# S6E2D5 register map
File version: 1.1
CPU: CM4 r0p1, little endian, MPU, FPU, 4 interrupt priority bits
Registers are 32-bit, read-write, reset 0x0 unless marked. A register's access mark holds for its fields unless they carry their own. Offsets are from the block's base; [hi:lo] are bit positions.

## CRC — CRC Registers
Base 0x40039000
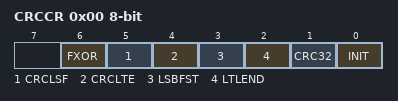
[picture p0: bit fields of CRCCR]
0x00 CRCCR 8-bit — CRC Control Register
  [6] FXOR — Initialization bit
  [5] CRCLSF — Final XOR control bit
  [4] CRCLTE — CRC result bit-order setting bit
  [3] LSBFST — CRC result byte-order setting bit
  [2] LTLEND — Bit-order setting bit
  [1] CRC32 — Byte-order setting bit
  [0] INIT — CRC mode selection bit
0x04 CRCINIT reset 0xFFFFFFFF — Initial Value Register
  [31:0] D — Initial value
0x08 CRCIN — Input Data Register
  [31:0] D — Input data
0x0C CRCR ro reset 0xFFFFFFFF — CRC Register
  [31:0] D — CRC Data

## WC — Watch Counter
Base 0x4003A000
0x00 WCRD 8-bit ro — Watch Counter Read Register
  [5:0] CTR — Counter read bits
0x01 WCRL 8-bit — Watch Counter Reload Register
  [5:0] RLC — Counter reload value setting bits
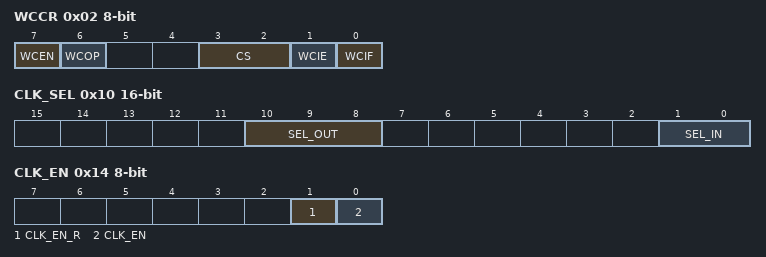
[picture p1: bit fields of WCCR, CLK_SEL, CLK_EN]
0x02 WCCR 8-bit — Watch Counter Control Register
  [7] WCEN — Watch counter operation enable bit
  [6] WCOP ro — Watch counter operating state flag
  [3:2] CS — Count clock select bits
  [1] WCIE — Interrupt request enable bit
  [0] WCIF — Interrupt request flag bit
0x10 CLK_SEL 16-bit — Clock Selection Register
  [10:8] SEL_OUT — Output clock selection bit
  [1:0] SEL_IN — Input clock selection bit
0x14 CLK_EN 8-bit — Division Clock Enable Register
  [1] CLK_EN_R — Division clock enable read bit
  [0] CLK_EN — Division clock enable bit

## LCR — Low-speed CR Prescaler
Base 0x4003C000
0x00 LCR_PRSLD 8-bit — Low-speed CR Prescaler Control Register
  [5:0] LCR_PRSLD — Low-speed CR Prescaler Load

## I2SPRE — I2S Clock Generation
Base 0x4003D000
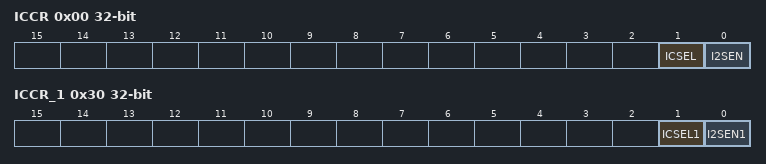
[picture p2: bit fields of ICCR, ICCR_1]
0x00 ICCR — I2S Clock Control Register
  [1] ICSEL — I2S clock selection bit
  [0] I2SEN — I2S clock output enable bit
0x04 IPCR1 — I2S-PLL Control Register 1
  [0] IPLLEN — I2S-PLL oscillation enable bit
0x08 IPCR2 — I2S-PLL Control Register 2
  [2:0] IPOWT — I2S-PLL oscillation stabilization wait time setting bits
0x0C IPCR3 reset 0x1 — I2S-PLL Control Register 3
  [4:0] IPLLK — Frequency division ratio (K) setting bits of the I2S-PLL clock
0x10 IPCR4 reset 0x1F — I2S-PLL Control Register 4
  [6:0] IPLLN — Frequency division ratio (N) setting bits of the I2S-PLL clock
0x14 IP_STR ro — I2S-PLL Status Register
  [0] IPRDY — I2S-PLL oscillation stabilization bit
0x18 IPINT_ENR — I2S-PLL Interrupt Factor Enable Register
  [0] IPCSE — I2S-PLL oscillation stabilization wait complete interrupt enable bit
0x1C IPINT_CLR wo — I2S-PLL Interrupt Factor Status Register
  [0] IPCSC — I2S-PLL interrupt factor status bit
0x20 IPINT_STR ro — I2S-PLL Interrupt Factor Clear Register
  [0] IPCSI — I2S-PLL oscillation stabilization interrupt factor clear bit
0x24 IPCR5 reset 0x18 — I2S-PLL Control Register 5
  [6:0] IPLLM — Frequency division ratio (M) setting bits of the I2S-PLL clock
0x30 ICCR_1 — I2S Clock Control Register
  [1] ICSEL1 — I2S clock selection bit
  [0] I2SEN1 — I2S clock output enable bit
0x34 IPCR5_1 reset 0x18 — I2S-PLL Control Register 5
  [6:0] IPLLM1 — Frequency division ratio (M) setting bits of the I2S-PLL clock

## GDCPRE — GDC Prescaler
Base 0x4003D100
0x00 GCCR — GSS Clock Control Register
  [0] GSSEN — GSS clock output enable/disable setting bit
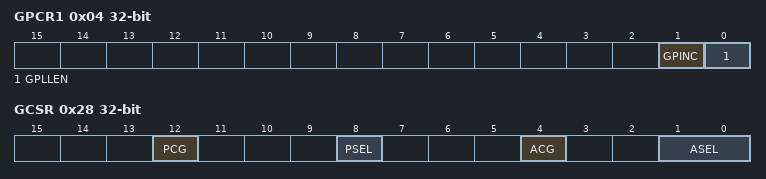
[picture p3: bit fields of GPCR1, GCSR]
0x04 GPCR1 — GSS PLL Control Register 1
  [1] GPINC — GDC PLL input clock selection bit
  [0] GPLLEN — GDC PLL enable/disable setting bit
0x08 GPCR2 — GSS PLL Control Register 2
  [2:0] GPOWT — PLL clock stabilization wait time set up bits
0x0C GPCR3 — GSS PLL Control Register 3
  [4:0] GPLLK — PLL input clock frequency division ratio setting bits
0x10 GPCR4 — GSS PLL Control Register 4
  [6:0] GPLLN — PLL feedback frequency division rasio seting bits
0x14 GP_STR ro — GSS PLL Status Register
  [0] GPRDY — GDC PLL status bit
0x18 GPINT_ENR — GSS PLL Interrupt Enable Register
  [0] GPCSE — PLL oscillation stabilization wait completion interrupt enable bit
0x1C GPINT_CLR — GSS PLL Interrupt Clear Register
  [0] GPCSC — GDC PLL oscillation stabilization wait completion interrupt clear bit
0x20 GPINT_STR ro — GSS PLL Status Register
  [0] GPCSI — GDC PLL oscillation stabilization wait completion interrupt status bit
0x28 GCSR — GSS Clock Select Register
  [12] PCG — HCLK Clock gating for Reference clock for Peripherals setting bit
  [8] PSEL — Peripheral clock for the GDC Sub system selection bit
  [4] ACG — Clock gating for Reference clock for GDC clock setting bit
  [1:0] ASEL — Reference clock for the GDC clock selection bits
0x2C GRCR — GSS Reset Control Register
  [0] RSTEN — Software reset for the GDC Sub system setting bit
0x30 GMCR — GSS Mode Control Register
  [0] TEN — PLL oscillation under case of TIMER mode control bit

## Notices in the file
Copyright (C) 2015 Spansion LLC. All Rights Reserved.
This software is owned and published by:
Spansion LLC, 915 DeGuigne Dr. Sunnyvale, CA  94088-3453 ("Spansion").
BY DOWNLOADING, INSTALLING OR USING THIS SOFTWARE, YOU AGREE TO BE BOUND
BY ALL THE TERMS AND CONDITIONS OF THIS AGREEMENT.
This software contains source code for use with Spansion
components. This software is licensed by Spansion to be adapted only
for use in systems utilizing Spansion components. Spansion shall not be
responsible for misuse or illegal use of this software for devices not
supported herein.  Spansion is providing this software "AS IS" and will
not be responsible for issues arising from incorrect user implementation
of the software.
SPANSION MAKES NO WARRANTY, EXPRESS OR IMPLIED, ARISING BY LAW OR OTHERWISE,
REGARDING THE SOFTWARE (INCLUDING ANY ACOOMPANYING WRITTEN MATERIALS),
ITS PERFORMANCE OR SUITABILITY FOR YOUR INTENDED USE, INCLUDING,
WITHOUT LIMITATION, THE IMPLIED WARRANTY OF MERCHANTABILITY, THE IMPLIED
WARRANTY OF FITNESS FOR A PARTICULAR PURPOSE OR USE, AND THE IMPLIED
WARRANTY OF NONINFRINGEMENT.
SPANSION SHALL HAVE NO LIABILITY (WHETHER IN CONTRACT, WARRANTY, TORT,
NEGLIGENCE OR OTHERWISE) FOR ANY DAMAGES WHATSOEVER (INCLUDING, WITHOUT
LIMITATION, DAMAGES FOR LOSS OF BUSINESS PROFITS, BUSINESS INTERRUPTION,
LOSS OF BUSINESS INFORMATION, OR OTHER PECUNIARY LOSS) ARISING FROM USE OR
INABILITY TO USE THE SOFTWARE, INCLUDING, WITHOUT LIMITATION, ANY DIRECT,
INDIRECT, INCIDENTAL, SPECIAL OR CONSEQUENTIAL DAMAGES OR LOSS OF DATA,
SAVINGS OR PROFITS,
EVEN IF SPANSION HAS BEEN ADVISED OF THE POSSIBILITY OF SUCH DAMAGES.
YOU ASSUME ALL RESPONSIBILITIES FOR SELECTION OF THE SOFTWARE TO ACHIEVE YOUR
INTENDED RESULTS, AND FOR THE INSTALLATION OF, USE OF, AND RESULTS OBTAINED
FROM, THE SOFTWARE.
This software may be replicated in part or whole for the licensed use,
with the restriction that this Disclaimer and Copyright notice must be
included with each copy of this software, whether used in part or whole,
at all times.
